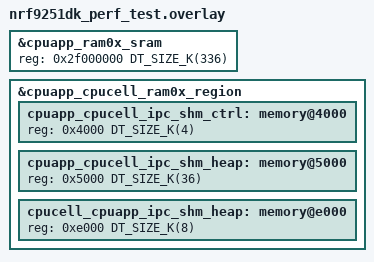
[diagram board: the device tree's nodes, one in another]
/*
 * Copyright (c) 2026 Nordic Semiconductor ASA
 *
 * SPDX-License-Identifier: LicenseRef-Nordic-5-Clause
 */

/delete-node/ &cpuapp_cpucell_ipc_shm_ctrl;
/delete-node/ &cpuapp_cpucell_ipc_shm_heap;
/delete-node/ &cpucell_cpuapp_ipc_shm_heap;

/* Reduce size of application RAM. */
&cpuapp_ram0x_sram {
	reg = <0x2f000000 DT_SIZE_K(336)>;
	ranges = <0x0 0x2f000000 0x54000>;
};

/* Bump TX buffer size to 36 kB. */
&cpuapp_cpucell_ram0x_region {
	cpuapp_cpucell_ipc_shm_ctrl: memory@4000 {
		reg = <0x4000 DT_SIZE_K(4)>;
	};

	cpuapp_cpucell_ipc_shm_heap: memory@5000 {
		reg = <0x5000 DT_SIZE_K(36)>;
	};

	cpucell_cpuapp_ipc_shm_heap: memory@e000 {
		reg = <0xe000 DT_SIZE_K(8)>;
	};
};
